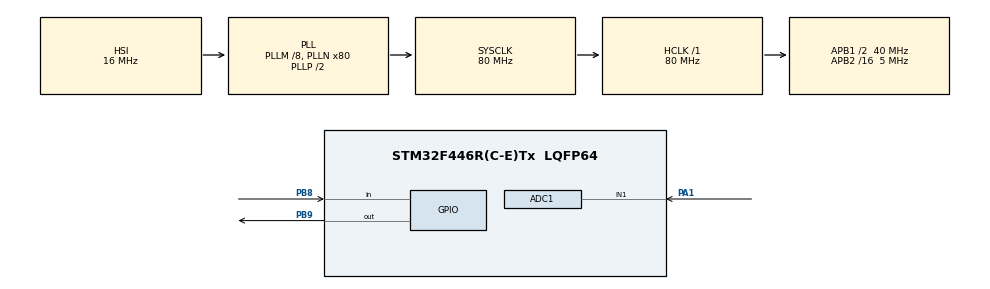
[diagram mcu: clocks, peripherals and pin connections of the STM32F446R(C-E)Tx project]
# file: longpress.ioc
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ADC1.Channel-1\#ChannelRegularConversion=ADC_CHANNEL_1
ADC1.NbrOfConversionFlag=1
ADC1.Rank-1\#ChannelRegularConversion=1
ADC1.SamplingTime-1\#ChannelRegularConversion=ADC_SAMPLETIME_3CYCLES
ADC1.master=1
Mcu.Family=STM32F4
Mcu.Name=STM32F446R(C-E)Tx
Mcu.Package=LQFP64
NVIC.PriorityGroup=NVIC_PRIORITYGROUP_4
PA1.Signal=ADCx_IN1
PB8.Signal=GPIO_Input
PB9.Signal=GPIO_Output
PH0-OSC_IN.Mode=HSE-External-Oscillator
PH0-OSC_IN.Signal=RCC_OSC_IN
PH1-OSC_OUT.Mode=HSE-External-Oscillator
PH1-OSC_OUT.Signal=RCC_OSC_OUT
ProjectManager.HeapSize=0x200
ProjectManager.StackSize=0x400
ProjectManager.TargetToolchain=STM32CubeIDE
RCC.AHBFreq_Value=80000000
RCC.APB1CLKDivider=RCC_HCLK_DIV2
RCC.APB1Freq_Value=40000000
RCC.APB1TimFreq_Value=80000000
RCC.APB2CLKDivider=RCC_HCLK_DIV16
RCC.APB2Freq_Value=5000000
RCC.APB2TimFreq_Value=10000000
RCC.CortexFreq_Value=80000000
RCC.HCLKFreq_Value=80000000
RCC.HSE_VALUE=8000000
RCC.PLLM=8
RCC.PLLN=80
RCC.SYSCLKFreq_VALUE=80000000
RCC.SYSCLKSource=RCC_SYSCLKSOURCE_PLLCLK
RCC.USBFreq_Value=80000000
RCC.VCOOutputFreq_Value=160000000
SH.ADCx_IN1.0=ADC1_IN1,IN1
TIM1.Period=0xffff-1
TIM1.Prescaler=10000-1
VP_TIM1_VS_ClockSourceINT.Mode=Internal
board=custom

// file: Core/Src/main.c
/* USER CODE BEGIN Header */
/**
  ******************************************************************************
  * @file           : main.c
  * @brief          : Main program body
  ******************************************************************************
  * @attention
  *
  * Copyright (c) 2023 STMicroelectronics.
  * All rights reserved.
  *
  * This software is licensed under terms that can be found in the LICENSE file
  * in the root directory of this software component.
  * If no LICENSE file comes with this software, it is provided AS-IS.
  *
  ******************************************************************************
  */
/* USER CODE END Header */
#include "main.h"
#include <stdbool.h>

ADC_HandleTypeDef hadc1;

TIM_HandleTypeDef htim1;

void SystemClock_Config(void);
static void MX_GPIO_Init(void);
static void MX_TIM1_Init(void);
static void MX_ADC1_Init(void);

/* USER CODE BEGIN 0 */
//void delay(uint16_t delay){
//	__HAL_TIM_SET_COUNTER(&htim8, 0);
//	while(__HAL_TIM_GET_COUNTER(&htim8)<delay);
//}

void blinkanje(uint16_t freq){
		HAL_GPIO_TogglePin(GPIOB, GPIO_PIN_9);
		HAL_Delay(freq);
}

//uint16_t odmerak(){
//
//}
/* USER CODE END 0 */

int main(void)
{
  /* USER CODE BEGIN 1 */
	uint8_t poslednjeStanje = GPIO_PIN_RESET;
	uint8_t trenutnoStanje;
	bool ledBlinking = false;
	uint16_t pressDuration = 0;
	uint16_t raw = 0;
  /* USER CODE END 1 */

  /* MCU Configuration--------------------------------------------------------*/

  /* Reset of all peripherals, Initializes the Flash interface and the Systick. */
  HAL_Init();

  /* Configure the system clock */
  SystemClock_Config();

  /* Initialize all configured peripherals */
  MX_GPIO_Init();
  MX_TIM1_Init();
  MX_ADC1_Init();
  /* USER CODE BEGIN 2 */
  HAL_TIM_Base_Start(&htim1);
  /* USER CODE END 2 */

  /* Infinite loop */
  /* USER CODE BEGIN WHILE */
  while (1)
  {
	  //HAL_GPIO_TogglePin(GPIOB, GPIO_PIN_9);
	  //delay(3000);

//	  while(HAL_GPIO_ReadPin(GPIOB, GPIO_PIN_8) == GPIO_PIN_SET)
//		  blinkanje();
	  if(ledBlinking == true) {
		  HAL_ADC_Start(&hadc1);
		  HAL_ADC_PollForConversion(&hadc1, HAL_MAX_DELAY);
		  raw = HAL_ADC_GetValue(&hadc1);
		  blinkanje(1100-raw/4);
	  }

	  trenutnoStanje = HAL_GPIO_ReadPin(GPIOB, GPIO_PIN_8);
	  if(poslednjeStanje == GPIO_PIN_RESET && trenutnoStanje == GPIO_PIN_SET)
		  __HAL_TIM_SET_COUNTER(&htim1, 0);
	  else if(poslednjeStanje == GPIO_PIN_SET && trenutnoStanje == GPIO_PIN_RESET)
		  pressDuration = __HAL_TIM_GET_COUNTER(&htim1);

	  if(pressDuration > 3000){
		  ledBlinking = !ledBlinking;
		  pressDuration = 0;
	  }

	  poslednjeStanje = trenutnoStanje;
    /* USER CODE END WHILE */

  }
}

void SystemClock_Config(void)
{
  RCC_OscInitTypeDef RCC_OscInitStruct = {0};
  RCC_ClkInitTypeDef RCC_ClkInitStruct = {0};

  /** Configure the main internal regulator output voltage
  */
  __HAL_RCC_PWR_CLK_ENABLE();
  __HAL_PWR_VOLTAGESCALING_CONFIG(PWR_REGULATOR_VOLTAGE_SCALE3);

  /** Initializes the RCC Oscillators according to the specified parameters
  * in the RCC_OscInitTypeDef structure.
  */
  RCC_OscInitStruct.OscillatorType = RCC_OSCILLATORTYPE_HSI;
  RCC_OscInitStruct.HSIState = RCC_HSI_ON;
  RCC_OscInitStruct.HSICalibrationValue = RCC_HSICALIBRATION_DEFAULT;
  RCC_OscInitStruct.PLL.PLLState = RCC_PLL_ON;
  RCC_OscInitStruct.PLL.PLLSource = RCC_PLLSOURCE_HSI;
  RCC_OscInitStruct.PLL.PLLM = 8;
  RCC_OscInitStruct.PLL.PLLN = 80;
  RCC_OscInitStruct.PLL.PLLP = RCC_PLLP_DIV2;
  RCC_OscInitStruct.PLL.PLLQ = 2;
  RCC_OscInitStruct.PLL.PLLR = 2;
  if (HAL_RCC_OscConfig(&RCC_OscInitStruct) != HAL_OK)
  {
    Error_Handler();
  }

  /** Initializes the CPU, AHB and APB buses clocks
  */
  RCC_ClkInitStruct.ClockType = RCC_CLOCKTYPE_HCLK|RCC_CLOCKTYPE_SYSCLK
                              |RCC_CLOCKTYPE_PCLK1|RCC_CLOCKTYPE_PCLK2;
  RCC_ClkInitStruct.SYSCLKSource = RCC_SYSCLKSOURCE_PLLCLK;
  RCC_ClkInitStruct.AHBCLKDivider = RCC_SYSCLK_DIV1;
  RCC_ClkInitStruct.APB1CLKDivider = RCC_HCLK_DIV2;
  RCC_ClkInitStruct.APB2CLKDivider = RCC_HCLK_DIV16;

  if (HAL_RCC_ClockConfig(&RCC_ClkInitStruct, FLASH_LATENCY_2) != HAL_OK)
  {
    Error_Handler();
  }
}

static void MX_ADC1_Init(void)
{

  ADC_ChannelConfTypeDef sConfig = {0};

  /** Configure the global features of the ADC (Clock, Resolution, Data Alignment and number of conversion)
  */
  hadc1.Instance = ADC1;
  hadc1.Init.ClockPrescaler = ADC_CLOCK_SYNC_PCLK_DIV2;
  hadc1.Init.Resolution = ADC_RESOLUTION_12B;
  hadc1.Init.ScanConvMode = DISABLE;
  hadc1.Init.ContinuousConvMode = DISABLE;
  hadc1.Init.DiscontinuousConvMode = DISABLE;
  hadc1.Init.ExternalTrigConvEdge = ADC_EXTERNALTRIGCONVEDGE_NONE;
  hadc1.Init.ExternalTrigConv = ADC_SOFTWARE_START;
  hadc1.Init.DataAlign = ADC_DATAALIGN_RIGHT;
  hadc1.Init.NbrOfConversion = 1;
  hadc1.Init.DMAContinuousRequests = DISABLE;
  hadc1.Init.EOCSelection = ADC_EOC_SINGLE_CONV;
  if (HAL_ADC_Init(&hadc1) != HAL_OK)
  {
    Error_Handler();
  }

  /** Configure for the selected ADC regular channel its corresponding rank in the sequencer and its sample time.
  */
  sConfig.Channel = ADC_CHANNEL_1;
  sConfig.Rank = 1;
  sConfig.SamplingTime = ADC_SAMPLETIME_3CYCLES;
  if (HAL_ADC_ConfigChannel(&hadc1, &sConfig) != HAL_OK)
  {
    Error_Handler();
  }

}

static void MX_TIM1_Init(void)
{

  TIM_ClockConfigTypeDef sClockSourceConfig = {0};
  TIM_MasterConfigTypeDef sMasterConfig = {0};

  htim1.Instance = TIM1;
  htim1.Init.Prescaler = 10000-1;
  htim1.Init.CounterMode = TIM_COUNTERMODE_UP;
  htim1.Init.Period = 0xffff-1;
  htim1.Init.ClockDivision = TIM_CLOCKDIVISION_DIV1;
  htim1.Init.RepetitionCounter = 0;
  htim1.Init.AutoReloadPreload = TIM_AUTORELOAD_PRELOAD_DISABLE;
  if (HAL_TIM_Base_Init(&htim1) != HAL_OK)
  {
    Error_Handler();
  }
  sClockSourceConfig.ClockSource = TIM_CLOCKSOURCE_INTERNAL;
  if (HAL_TIM_ConfigClockSource(&htim1, &sClockSourceConfig) != HAL_OK)
  {
    Error_Handler();
  }
  sMasterConfig.MasterOutputTrigger = TIM_TRGO_RESET;
  sMasterConfig.MasterSlaveMode = TIM_MASTERSLAVEMODE_DISABLE;
  if (HAL_TIMEx_MasterConfigSynchronization(&htim1, &sMasterConfig) != HAL_OK)
  {
    Error_Handler();
  }

}

static void MX_GPIO_Init(void)
{
  GPIO_InitTypeDef GPIO_InitStruct = {0};

  /* GPIO Ports Clock Enable */
  __HAL_RCC_GPIOH_CLK_ENABLE();
  __HAL_RCC_GPIOA_CLK_ENABLE();
  __HAL_RCC_GPIOB_CLK_ENABLE();

  /*Configure GPIO pin Output Level */
  HAL_GPIO_WritePin(GPIOB, GPIO_PIN_9, GPIO_PIN_RESET);

  /*Configure GPIO pin : PB8 */
  GPIO_InitStruct.Pin = GPIO_PIN_8;
  GPIO_InitStruct.Mode = GPIO_MODE_INPUT;
  GPIO_InitStruct.Pull = GPIO_NOPULL;
  HAL_GPIO_Init(GPIOB, &GPIO_InitStruct);

  /*Configure GPIO pin : PB9 */
  GPIO_InitStruct.Pin = GPIO_PIN_9;
  GPIO_InitStruct.Mode = GPIO_MODE_OUTPUT_PP;
  GPIO_InitStruct.Pull = GPIO_NOPULL;
  GPIO_InitStruct.Speed = GPIO_SPEED_FREQ_LOW;
  HAL_GPIO_Init(GPIOB, &GPIO_InitStruct);

}

void Error_Handler(void)
{
  __disable_irq();
  while (1)
  {
  }
}
